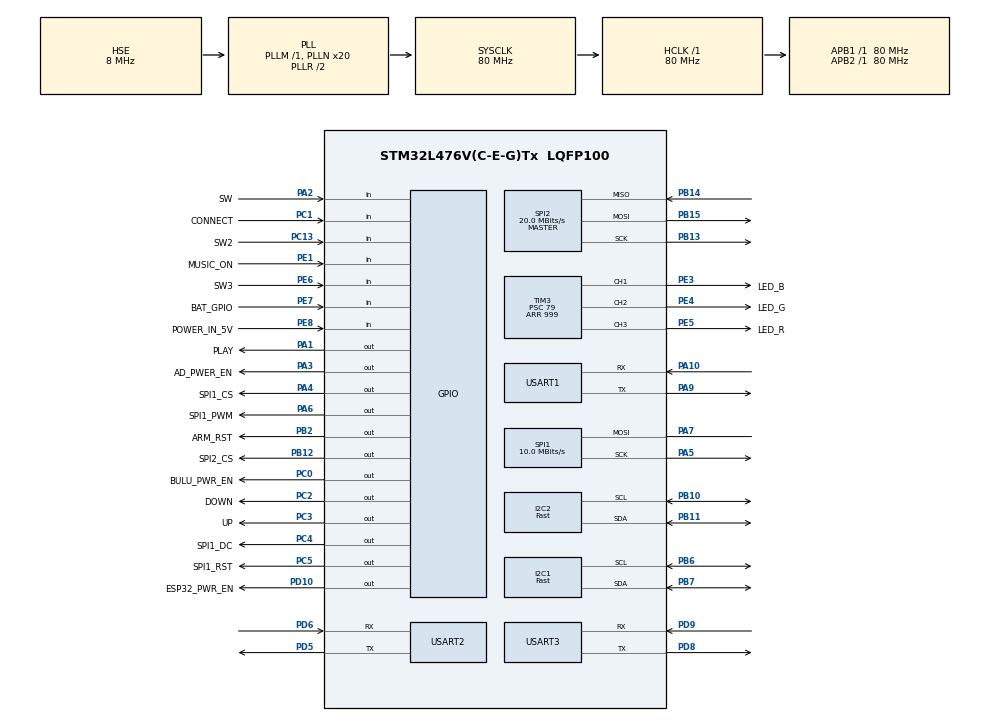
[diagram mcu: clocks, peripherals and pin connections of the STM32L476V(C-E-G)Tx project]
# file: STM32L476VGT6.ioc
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Dma.Request0=USART1_RX
Dma.USART1_RX.0.Direction=DMA_PERIPH_TO_MEMORY
Dma.USART1_RX.0.Instance=DMA1_Channel5
Dma.USART1_RX.0.MemDataAlignment=DMA_MDATAALIGN_BYTE
Dma.USART1_RX.0.MemInc=DMA_MINC_ENABLE
Dma.USART1_RX.0.Mode=DMA_CIRCULAR
Dma.USART1_RX.0.PeriphDataAlignment=DMA_PDATAALIGN_BYTE
Dma.USART1_RX.0.PeriphInc=DMA_PINC_DISABLE
Dma.USART1_RX.0.Priority=DMA_PRIORITY_LOW
FREERTOS.Tasks01=defaultTask,24,128,StartDefaultTask,Default,NULL,Dynamic,NULL,NULL
FREERTOS.configTOTAL_HEAP_SIZE=30000
I2C1.I2C_Speed_Mode=I2C_Fast
I2C1.Speed=400
I2C1.Timing=0x00F12981
I2C2.I2C_Speed_Mode=I2C_Fast
I2C2.Speed=400
I2C2.Timing=0x00F12981
Mcu.Family=STM32L4
Mcu.Name=STM32L476V(C-E-G)Tx
Mcu.Package=LQFP100
NVIC.DMA1_Channel5_IRQn=true\:5\:0\:false\:false\:true\:true\:false\:true\:true
NVIC.PriorityGroup=NVIC_PRIORITYGROUP_4
NVIC.TIM6_DAC_IRQn=true\:15\:0\:false\:false\:true\:false\:false\:true\:true
NVIC.TimeBase=TIM6_DAC_IRQn
NVIC.TimeBaseIP=TIM6
NVIC.USART1_IRQn=true\:5\:0\:false\:false\:true\:true\:true\:true\:true
PA0.Mode=SYS_WakeUp0
PA0.Signal=SYS_WKUP1
PA1.GPIO_Label=PLAY
PA1.GPIO_PuPd=GPIO_NOPULL
PA1.Signal=GPIO_Output
PA10.Mode=Asynchronous
PA10.Signal=USART1_RX
PA13\ (JTMS-SWDIO).Mode=Serial_Wire
PA13\ (JTMS-SWDIO).Signal=SYS_JTMS-SWDIO
PA14\ (JTCK-SWCLK).Mode=Serial_Wire
PA14\ (JTCK-SWCLK).Signal=SYS_JTCK-SWCLK
PA2.GPIO_Label=SW
PA2.GPIO_PuPd=GPIO_PULLUP
PA2.Signal=GPIO_Input
PA3.GPIO_Label=AD_PWER_EN
PA3.PinState=GPIO_PIN_RESET
PA3.Signal=GPIO_Output
PA4.GPIO_Label=SPI1_CS
PA4.GPIO_Speed=GPIO_SPEED_FREQ_HIGH
PA4.PinState=GPIO_PIN_SET
PA4.Signal=GPIO_Output
PA5.Mode=Simplex_Bidirectional_Master
PA5.Signal=SPI1_SCK
PA6.GPIO_Label=SPI1_PWM
PA6.GPIO_Speed=GPIO_SPEED_FREQ_HIGH
PA6.Signal=GPIO_Output
PA7.Mode=Simplex_Bidirectional_Master
PA7.Signal=SPI1_MOSI
PA9.Mode=Asynchronous
PA9.Signal=USART1_TX
PB10.Mode=I2C
PB10.Signal=I2C2_SCL
PB11.Mode=I2C
PB11.Signal=I2C2_SDA
PB12.GPIO_Label=SPI2_CS
PB12.GPIO_Speed=GPIO_SPEED_FREQ_HIGH
PB12.PinState=GPIO_PIN_SET
PB12.Signal=GPIO_Output
PB13.Mode=Full_Duplex_Master
PB13.Signal=SPI2_SCK
PB14.Mode=Full_Duplex_Master
PB14.Signal=SPI2_MISO
PB15.Mode=Full_Duplex_Master
PB15.Signal=SPI2_MOSI
PB2.GPIO_Label=ARM_RST
PB2.GPIO_Speed=GPIO_SPEED_FREQ_LOW
PB2.PinState=GPIO_PIN_RESET
PB2.Signal=GPIO_Output
PB6.Mode=I2C
PB6.Signal=I2C1_SCL
PB7.Mode=I2C
PB7.Signal=I2C1_SDA
PC0.GPIO_Label=BULU_PWR_EN
PC0.PinState=GPIO_PIN_SET
PC0.Signal=GPIO_Output
PC1.GPIO_Label=CONNECT
PC1.Signal=GPIO_Input
PC13.GPIO_Label=SW2
PC13.GPIO_PuPd=GPIO_PULLUP
PC13.Signal=GPIO_Input
PC14-OSC32_IN\ (PC14).Mode=LSE-External-Oscillator
PC14-OSC32_IN\ (PC14).Signal=RCC_OSC32_IN
PC15-OSC32_OUT\ (PC15).Mode=LSE-External-Oscillator
PC15-OSC32_OUT\ (PC15).Signal=RCC_OSC32_OUT
PC2.GPIO_Label=DOWN
PC2.Signal=GPIO_Output
PC3.GPIO_Label=UP
PC3.Signal=GPIO_Output
PC4.GPIO_Label=SPI1_DC
PC4.GPIO_Speed=GPIO_SPEED_FREQ_HIGH
PC4.PinState=GPIO_PIN_SET
PC4.Signal=GPIO_Output
PC5.GPIO_Label=SPI1_RST
PC5.GPIO_Speed=GPIO_SPEED_FREQ_HIGH
PC5.PinState=GPIO_PIN_SET
PC5.Signal=GPIO_Output
PD10.GPIO_Label=ESP32_PWR_EN
PD10.PinState=GPIO_PIN_SET
PD10.Signal=GPIO_Output
PD5.Mode=Asynchronous
PD5.Signal=USART2_TX
PD6.Mode=Asynchronous
PD6.Signal=USART2_RX
PD8.Mode=Asynchronous
PD8.Signal=USART3_TX
PD9.Mode=Asynchronous
PD9.Signal=USART3_RX
PE1.GPIO_Label=MUSIC_ON
PE1.Signal=GPIO_Input
PE3.GPIO_Label=LED_B
PE3.Signal=S_TIM3_CH1
PE4.GPIO_Label=LED_G
PE4.Signal=S_TIM3_CH2
PE5.GPIO_Label=LED_R
PE5.Signal=S_TIM3_CH3
PE6.GPIO_Label=SW3
PE6.GPIO_PuPd=GPIO_PULLUP
PE6.Signal=GPIO_Input
PE7.GPIO_Label=BAT_GPIO
PE7.Signal=GPIO_Input
PE8.GPIO_Label=POWER_IN_5V
PE8.Signal=GPIO_Input
PH0-OSC_IN\ (PH0).Mode=HSE-External-Oscillator
PH0-OSC_IN\ (PH0).Signal=RCC_OSC_IN
PH1-OSC_OUT\ (PH1).Mode=HSE-External-Oscillator
PH1-OSC_OUT\ (PH1).Signal=RCC_OSC_OUT
ProjectManager.HeapSize=0x800
ProjectManager.StackSize=0x1000
ProjectManager.TargetToolchain=MDK-ARM V5.32
RCC.ADCFreq_Value=96000000
RCC.AHBFreq_Value=80000000
RCC.APB1Freq_Value=80000000
RCC.APB1TimFreq_Value=80000000
RCC.APB2Freq_Value=80000000
RCC.APB2TimFreq_Value=80000000
RCC.CortexFreq_Value=80000000
RCC.HCLKFreq_Value=80000000
RCC.HSE_VALUE=8000000
RCC.HSI_VALUE=16000000
RCC.MSI_VALUE=4000000
RCC.PLLN=20
RCC.PLLSAI1N=24
RCC.PLLSourceVirtual=RCC_PLLSOURCE_HSE
RCC.RTCClockSelection=RCC_RTCCLKSOURCE_LSE
RCC.SYSCLKFreq_VALUE=80000000
RCC.SYSCLKSource=RCC_SYSCLKSOURCE_PLLCLK
RCC.USBFreq_Value=96000000
RCC.VCOOutputFreq_Value=160000000
SH.S_TIM3_CH1.0=TIM3_CH1,PWM Generation1 CH1
SH.S_TIM3_CH2.0=TIM3_CH2,PWM Generation2 CH2
SH.S_TIM3_CH3.0=TIM3_CH3,PWM Generation3 CH3
SPI1.BaudRatePrescaler=SPI_BAUDRATEPRESCALER_8
SPI1.CalculateBaudRate=10.0 MBits/s
SPI1.DataSize=SPI_DATASIZE_8BIT
SPI1.Direction=SPI_DIRECTION_1LINE
SPI1.Mode=SPI_MODE_MASTER
SPI1.VirtualType=VM_MASTER
SPI2.BaudRatePrescaler=SPI_BAUDRATEPRESCALER_4
SPI2.CalculateBaudRate=20.0 MBits/s
SPI2.DataSize=SPI_DATASIZE_8BIT
SPI2.Direction=SPI_DIRECTION_2LINES
SPI2.Mode=SPI_MODE_MASTER
SPI2.VirtualType=VM_MASTER
TIM3.AutoReloadPreload=TIM_AUTORELOAD_PRELOAD_ENABLE
TIM3.Channel-PWM\ Generation1\ CH1=TIM_CHANNEL_1
TIM3.Channel-PWM\ Generation2\ CH2=TIM_CHANNEL_2
TIM3.Channel-PWM\ Generation3\ CH3=TIM_CHANNEL_3
TIM3.Period=999
TIM3.Prescaler=79
TIM3.Pulse-PWM\ Generation1\ CH1=500
TIM3.Pulse-PWM\ Generation2\ CH2=500
TIM3.Pulse-PWM\ Generation3\ CH3=500
USART1.SwapParam=ADVFEATURE_SWAP_DISABLE
USART1.VirtualMode-Asynchronous=VM_ASYNC
USART2.VirtualMode-Asynchronous=VM_ASYNC
USART3.VirtualMode-Asynchronous=VM_ASYNC
VP_FREERTOS_VS_CMSIS_V2.Mode=CMSIS_V2
VP_SYS_VS_tim6.Mode=TIM6
VP_TIM3_VS_ClockSourceINT.Mode=Internal
board=custom

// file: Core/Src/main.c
/* USER CODE BEGIN Header */
/**
  ******************************************************************************
  * @file           : main.c
  * @brief          : Main program body
  ******************************************************************************
  * @attention
  *
  * Copyright (c) 2026 STMicroelectronics.
  * All rights reserved.
  *
  * This software is licensed under terms that can be found in the LICENSE file
  * in the root directory of this software component.
  * If no LICENSE file comes with this software, it is provided AS-IS.
  *
  ******************************************************************************
  */
/* USER CODE END Header */
#include "main.h"
#include "cmsis_os.h"
#include "dma.h"
#include "i2c.h"
#include "spi.h"
#include "tim.h"
#include "usart.h"
#include "gpio.h"

/* USER CODE BEGIN Includes */
#include "log.h"
//#include "st7789.h"
//#include "aht20.h"

//#include "eeprom.h"    // 你的驱动
//#include "eeprom_app.h"
/* USER CODE END Includes */

void SystemClock_Config(void);
void MX_FREERTOS_Init(void);

int main(void)
{

  /* MCU Configuration--------------------------------------------------------*/

  /* Reset of all peripherals, Initializes the Flash interface and the Systick. */
  HAL_Init();

  /* Configure the system clock */
  SystemClock_Config();

  /* Initialize all configured peripherals */
  MX_GPIO_Init();
  MX_DMA_Init();
  MX_SPI1_Init();
  MX_USART2_UART_Init();
  MX_I2C1_Init();
  MX_TIM3_Init();
  MX_I2C2_Init();
  MX_SPI2_Init();
  MX_USART1_UART_Init();
  MX_USART3_UART_Init();
  /* USER CODE BEGIN 2 */
 log_init(&huart3);

log_printf("system start");
// ST7789_Init();
// HAL_GPIO_WritePin(SPI1_PWM_GPIO_Port, SPI1_PWM_Pin, GPIO_PIN_SET);
//	ST7789_Fill_Color(BLACK);
//
// // 定义变量
// float temp, humi;
//   AHT20_Init(&hi2c1);

//     if (!EE24_Init(&ee_chip, &hi2c1, EE24_ADDRESS_DEFAULT))
//     {
//         log_printf("EEPROM Init FAIL");
//     }
//     else
//     {
//         log_printf("EEPROM Init OK");
//     }
  /* USER CODE END 2 */

  /* Init scheduler */
  osKernelInitialize();  /* Call init function for freertos objects (in cmsis_os2.c) */
  MX_FREERTOS_Init();

  /* Start scheduler */
  osKernelStart();

  /* We should never get here as control is now taken by the scheduler */

  /* Infinite loop */
  while (1)
  {

    /* USER CODE BEGIN 3 */
    // log_printf("system runing");
    // I2C_ScanDevices();  // 扫描设备

    //  AHT20_Read(&hi2c1, &temp, &humi);

    // log_printf("temp: %f\r\n", temp);
    // log_printf("humi: %f\r\n", humi);
    // HAL_Delay(1000);

// ST7789_Fill_Color(RED);
// HAL_Delay(2000);
// ST7789_Fill_Color(GREEN);
// HAL_Delay(2000);
// ST7789_Fill_Color(BLUE);
// HAL_Delay(2000);
// 	ST7789_Fill_Color(BLACK);
// 		HAL_Delay(2000);

  }
  /* USER CODE END 3 */
}

void SystemClock_Config(void)
{
  RCC_OscInitTypeDef RCC_OscInitStruct = {0};
  RCC_ClkInitTypeDef RCC_ClkInitStruct = {0};

  /** Configure the main internal regulator output voltage
  */
  if (HAL_PWREx_ControlVoltageScaling(PWR_REGULATOR_VOLTAGE_SCALE1) != HAL_OK)
  {
    Error_Handler();
  }

  /** Initializes the RCC Oscillators according to the specified parameters
  * in the RCC_OscInitTypeDef structure.
  */
  RCC_OscInitStruct.OscillatorType = RCC_OSCILLATORTYPE_HSE;
  RCC_OscInitStruct.HSEState = RCC_HSE_ON;
  RCC_OscInitStruct.PLL.PLLState = RCC_PLL_ON;
  RCC_OscInitStruct.PLL.PLLSource = RCC_PLLSOURCE_HSE;
  RCC_OscInitStruct.PLL.PLLM = 1;
  RCC_OscInitStruct.PLL.PLLN = 20;
  RCC_OscInitStruct.PLL.PLLP = RCC_PLLP_DIV7;
  RCC_OscInitStruct.PLL.PLLQ = RCC_PLLQ_DIV2;
  RCC_OscInitStruct.PLL.PLLR = RCC_PLLR_DIV2;
  if (HAL_RCC_OscConfig(&RCC_OscInitStruct) != HAL_OK)
  {
    Error_Handler();
  }

  /** Initializes the CPU, AHB and APB buses clocks
  */
  RCC_ClkInitStruct.ClockType = RCC_CLOCKTYPE_HCLK|RCC_CLOCKTYPE_SYSCLK
                              |RCC_CLOCKTYPE_PCLK1|RCC_CLOCKTYPE_PCLK2;
  RCC_ClkInitStruct.SYSCLKSource = RCC_SYSCLKSOURCE_PLLCLK;
  RCC_ClkInitStruct.AHBCLKDivider = RCC_SYSCLK_DIV1;
  RCC_ClkInitStruct.APB1CLKDivider = RCC_HCLK_DIV1;
  RCC_ClkInitStruct.APB2CLKDivider = RCC_HCLK_DIV1;

  if (HAL_RCC_ClockConfig(&RCC_ClkInitStruct, FLASH_LATENCY_4) != HAL_OK)
  {
    Error_Handler();
  }
}

void HAL_TIM_PeriodElapsedCallback(TIM_HandleTypeDef *htim)
{
  if (htim->Instance == TIM6)
  {
    HAL_IncTick();
  }
}

void Error_Handler(void)
{
  __disable_irq();
  while (1)
  {
  }
}

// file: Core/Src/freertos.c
/* USER CODE BEGIN Header */
/**
  ******************************************************************************
  * File Name          : freertos.c
  * Description        : Code for freertos applications
  ******************************************************************************
  * @attention
  *
  * Copyright (c) 2026 STMicroelectronics.
  * All rights reserved.
  *
  * This software is licensed under terms that can be found in the LICENSE file
  * in the root directory of this software component.
  * If no LICENSE file comes with this software, it is provided AS-IS.
  *
  ******************************************************************************
  */
/* USER CODE END Header */

#include "FreeRTOS.h"
#include "task.h"
#include "main.h"
#include "cmsis_os.h"

/* USER CODE BEGIN Includes */
#include "log.h"
#include "rtos_app.h"
/* USER CODE END Includes */

/* Definitions for defaultTask */
osThreadId_t defaultTaskHandle;
const osThreadAttr_t defaultTask_attributes = {
  .name = "defaultTask",
  .stack_size = 128 * 4,
  .priority = (osPriority_t) osPriorityNormal,
};

void StartDefaultTask(void *argument);

void MX_FREERTOS_Init(void); /* (MISRA C 2004 rule 8.1) */

void MX_FREERTOS_Init(void) {

  /* Create the thread(s) */
  /* creation of defaultTask */
  defaultTaskHandle = osThreadNew(StartDefaultTask, NULL, &defaultTask_attributes);

  /* USER CODE BEGIN RTOS_THREADS */
  /* add threads, ... */
    myTask();
  /* USER CODE END RTOS_THREADS */

}

void StartDefaultTask(void *argument)
{
  /* USER CODE BEGIN StartDefaultTask */
  /* Infinite loop */
  for(;;)
  {
    // log_printf("default task running");
    osDelay(5000);
  }
  /* USER CODE END StartDefaultTask */
}
